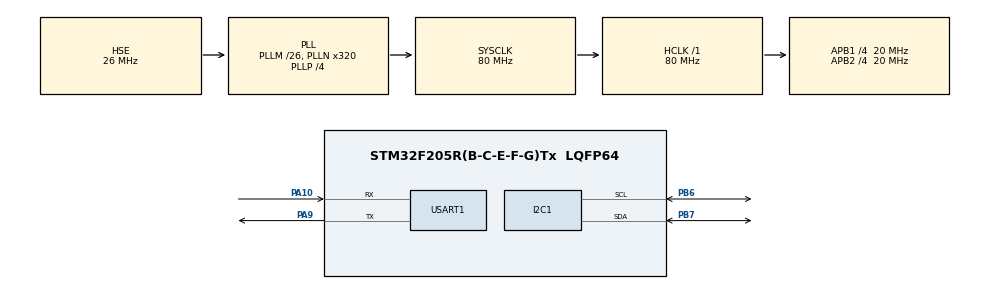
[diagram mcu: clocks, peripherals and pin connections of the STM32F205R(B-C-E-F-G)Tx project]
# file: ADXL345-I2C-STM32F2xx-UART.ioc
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I2C1.I2C_Mode=I2C_Standard
I2C1.OwnAddress=0x53
Mcu.Family=STM32F2
Mcu.Name=STM32F205R(B-C-E-F-G)Tx
Mcu.Package=LQFP64
NVIC.PriorityGroup=NVIC_PRIORITYGROUP_4
NVIC.TIM2_IRQn=true\:0\:0\:false\:false\:true\:true
NVIC.USART1_IRQn=true\:0\:0\:false\:false\:true\:true
PA10.GPIO_Speed=GPIO_SPEED_FREQ_HIGH
PA10.Mode=Asynchronous
PA10.Signal=USART1_RX
PA13.Mode=Serial_Wire
PA13.Signal=SYS_JTMS-SWDIO
PA14.Mode=Serial_Wire
PA14.Signal=SYS_JTCK-SWCLK
PA9.GPIO_Speed=GPIO_SPEED_FREQ_HIGH
PA9.Mode=Asynchronous
PA9.Signal=USART1_TX
PB6.GPIO_PuPdOD=GPIO_NOPULL
PB6.Mode=I2C
PB6.Signal=I2C1_SCL
PB7.GPIO_PuPdOD=GPIO_NOPULL
PB7.Mode=I2C
PB7.Signal=I2C1_SDA
PH0-OSC_IN.Mode=HSE-External-Oscillator
PH0-OSC_IN.Signal=RCC_OSC_IN
PH1-OSC_OUT.Mode=HSE-External-Oscillator
PH1-OSC_OUT.Signal=RCC_OSC_OUT
ProjectManager.HeapSize=0x400
ProjectManager.StackSize=0x200
ProjectManager.TargetToolchain=MDK-ARM V5
RCC.48MHZClocksFreq_Value=80000000
RCC.AHBFreq_Value=80000000
RCC.APB1CLKDivider=RCC_HCLK_DIV4
RCC.APB1Freq_Value=20000000
RCC.APB1TimFreq_Value=40000000
RCC.APB2CLKDivider=RCC_HCLK_DIV4
RCC.APB2Freq_Value=20000000
RCC.APB2TimFreq_Value=40000000
RCC.CortexFreq_Value=80000000
RCC.HCLKFreq_Value=80000000
RCC.HSE_VALUE=26000000
RCC.HSI_VALUE=16000000
RCC.LSE_VALUE=32768
RCC.PLLM=26
RCC.PLLN=320
RCC.PLLP=RCC_PLLP_DIV4
RCC.PLLSourceVirtual=RCC_PLLSOURCE_HSE
RCC.SYSCLKFreq_VALUE=80000000
RCC.SYSCLKSource=RCC_SYSCLKSOURCE_PLLCLK
RCC.VCOOutputFreq_Value=320000000
TIM2.Period=5000
TIM2.Prescaler=40000
TIM2.TIM_MasterOutputTrigger=TIM_TRGO_UPDATE
USART1.VirtualMode=VM_ASYNC
VP_TIM2_VS_ClockSourceINT.Mode=Internal
board=I2C_emw3162_Cube

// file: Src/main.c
/**
  ******************************************************************************
  * @file           : main.c
  * @brief          : Main program body
  ******************************************************************************
  ** This notice applies to any and all portions of this file
  * that are not between comment pairs USER CODE BEGIN and
  * USER CODE END. Other portions of this file, whether
  * inserted by the user or by software development tools
  * are owned by their respective copyright owners.
  *
  * COPYRIGHT(c) 2018 STMicroelectronics
																																				 CEBRIАN
  ******************************************************************************
  */
#include "main.h"
#include "stm32f2xx_hal.h"

/* USER CODE BEGIN Includes */
#include "ADXL345_Library.h"

/* USER CODE END Includes */

I2C_HandleTypeDef hi2c1;
TIM_HandleTypeDef htim2;
UART_HandleTypeDef huart1;

/* USER CODE BEGIN PV */
/* Private variables ---------------------------------------------------------*/

/* USER CODE END PV */

void SystemClock_Config(void);
static void MX_GPIO_Init(void);
static void MX_I2C1_Init(void);
static void MX_TIM2_Init(void);
static void MX_USART1_UART_Init(void);

/* USER CODE BEGIN PFP */
/* Private function prototypes -----------------------------------------------*/

/* USER CODE END PFP */

int main(void)
{

  /* MCU Configuration----------------------------------------------------------*/

  /* Reset of all peripherals, Initializes the Flash interface and the Systick. */
  HAL_Init();

  /* Configure the system clock */
  SystemClock_Config();

  /* Initialize all configured peripherals */
  MX_GPIO_Init();
  MX_I2C1_Init();
  MX_TIM2_Init();
  MX_USART1_UART_Init();
  /* USER CODE BEGIN 2 */
	UARTInterface();
  /* USER CODE END 2 */

  /* Infinite loop */
  while (1)
  {

  }

}

void SystemClock_Config(void)
{

  RCC_OscInitTypeDef RCC_OscInitStruct;
  RCC_ClkInitTypeDef RCC_ClkInitStruct;

    /**Initializes the CPU, AHB and APB busses clocks
    */
  RCC_OscInitStruct.OscillatorType = RCC_OSCILLATORTYPE_HSE;
  RCC_OscInitStruct.HSEState = RCC_HSE_ON;
  RCC_OscInitStruct.PLL.PLLState = RCC_PLL_ON;
  RCC_OscInitStruct.PLL.PLLSource = RCC_PLLSOURCE_HSE;
  RCC_OscInitStruct.PLL.PLLM = 26;
  RCC_OscInitStruct.PLL.PLLN = 320;
  RCC_OscInitStruct.PLL.PLLP = RCC_PLLP_DIV4;
  RCC_OscInitStruct.PLL.PLLQ = 4;
  if (HAL_RCC_OscConfig(&RCC_OscInitStruct) != HAL_OK)
  {
    _Error_Handler(__FILE__, __LINE__);
  }

    /**Initializes the CPU, AHB and APB busses clocks
    */
  RCC_ClkInitStruct.ClockType = RCC_CLOCKTYPE_HCLK|RCC_CLOCKTYPE_SYSCLK
                              |RCC_CLOCKTYPE_PCLK1|RCC_CLOCKTYPE_PCLK2;
  RCC_ClkInitStruct.SYSCLKSource = RCC_SYSCLKSOURCE_PLLCLK;
  RCC_ClkInitStruct.AHBCLKDivider = RCC_SYSCLK_DIV1;
  RCC_ClkInitStruct.APB1CLKDivider = RCC_HCLK_DIV4;
  RCC_ClkInitStruct.APB2CLKDivider = RCC_HCLK_DIV4;

  if (HAL_RCC_ClockConfig(&RCC_ClkInitStruct, FLASH_LATENCY_2) != HAL_OK)
  {
    _Error_Handler(__FILE__, __LINE__);
  }

    /**Configure the Systick interrupt time
    */
  HAL_SYSTICK_Config(HAL_RCC_GetHCLKFreq()/1000);

    /**Configure the Systick
    */
  HAL_SYSTICK_CLKSourceConfig(SYSTICK_CLKSOURCE_HCLK);

  /* SysTick_IRQn interrupt configuration */
  HAL_NVIC_SetPriority(SysTick_IRQn, 0, 0);
}

/* I2C1 init function */
static void MX_I2C1_Init(void)
{

  hi2c1.Instance = I2C1;
  hi2c1.Init.ClockSpeed = 100000;
  hi2c1.Init.DutyCycle = I2C_DUTYCYCLE_2;
  hi2c1.Init.OwnAddress1 = 166;
  hi2c1.Init.AddressingMode = I2C_ADDRESSINGMODE_7BIT;
  hi2c1.Init.DualAddressMode = I2C_DUALADDRESS_DISABLE;
  hi2c1.Init.OwnAddress2 = 0;
  hi2c1.Init.GeneralCallMode = I2C_GENERALCALL_DISABLE;
  hi2c1.Init.NoStretchMode = I2C_NOSTRETCH_DISABLE;
  if (HAL_I2C_Init(&hi2c1) != HAL_OK)
  {
    _Error_Handler(__FILE__, __LINE__);
  }

}

/* TIM2 init function */
static void MX_TIM2_Init(void)
{

  TIM_ClockConfigTypeDef sClockSourceConfig;
  TIM_MasterConfigTypeDef sMasterConfig;
  htim2.Instance = TIM2;
  htim2.Init.Prescaler = 40000;
  htim2.Init.CounterMode = TIM_COUNTERMODE_UP;
  htim2.Init.Period = 5000 + 1;
  htim2.Init.ClockDivision = TIM_CLOCKDIVISION_DIV1;
//  htim2.Init.AutoReloadPreload = TIM_AUTORELOAD_PRELOAD_DISABLE;
  if (HAL_TIM_Base_Init(&htim2) != HAL_OK)
  {
    _Error_Handler(__FILE__, __LINE__);
  }

  sClockSourceConfig.ClockSource = TIM_CLOCKSOURCE_INTERNAL;
  if (HAL_TIM_ConfigClockSource(&htim2, &sClockSourceConfig) != HAL_OK)
  {
    _Error_Handler(__FILE__, __LINE__);
  }

  sMasterConfig.MasterOutputTrigger = TIM_TRGO_UPDATE;
  sMasterConfig.MasterSlaveMode = TIM_MASTERSLAVEMODE_DISABLE;
  if (HAL_TIMEx_MasterConfigSynchronization(&htim2, &sMasterConfig) != HAL_OK)
  {
    _Error_Handler(__FILE__, __LINE__);
  }

}

/* USART1 init function */
static void MX_USART1_UART_Init(void)
{

  huart1.Instance = USART1;
  huart1.Init.BaudRate = 115200;
  huart1.Init.WordLength = UART_WORDLENGTH_8B;
  huart1.Init.StopBits = UART_STOPBITS_1;
  huart1.Init.Parity = UART_PARITY_NONE;
  huart1.Init.Mode = UART_MODE_TX_RX;
  huart1.Init.HwFlowCtl = UART_HWCONTROL_NONE;
  huart1.Init.OverSampling = UART_OVERSAMPLING_16;
  if (HAL_UART_Init(&huart1) != HAL_OK)
  {
    _Error_Handler(__FILE__, __LINE__);
  }

}

/** Configure pins as
        * Analog
        * Input
        * Output
        * EVENT_OUT
        * EXTI
*/
static void MX_GPIO_Init(void)
{

  /* GPIO Ports Clock Enable */
  __HAL_RCC_GPIOH_CLK_ENABLE();
  __HAL_RCC_GPIOA_CLK_ENABLE();
  __HAL_RCC_GPIOB_CLK_ENABLE();

}

void _Error_Handler(char *file, int line)
{
  while(1)
  {
  }
}

/************************ (C) COPYRIGHT STMicroelectronics *****END OF FILE****/
